# V32F20x_CM33 register map
File version: 1.0.3
CPU: CM33 r0p4, little endian, MPU, FPU, DSP, 3 interrupt priority bits, 8 SAU regions
Registers are 32-bit, read-write, reset 0x0 unless marked. A register's access mark holds for its fields unless they carry their own. Offsets are from the block's base; [hi:lo] are bit positions; lines under a group give offsets from that group; {n}, {i} and the like mark numbered series.

## ADC0 — ADC0 Peripheral Interface
Base 0x400A1000
Same registers: ADC1 0x400A1100, SEC_ADC0 0x500A1000, SEC_ADC1 0x500A1100
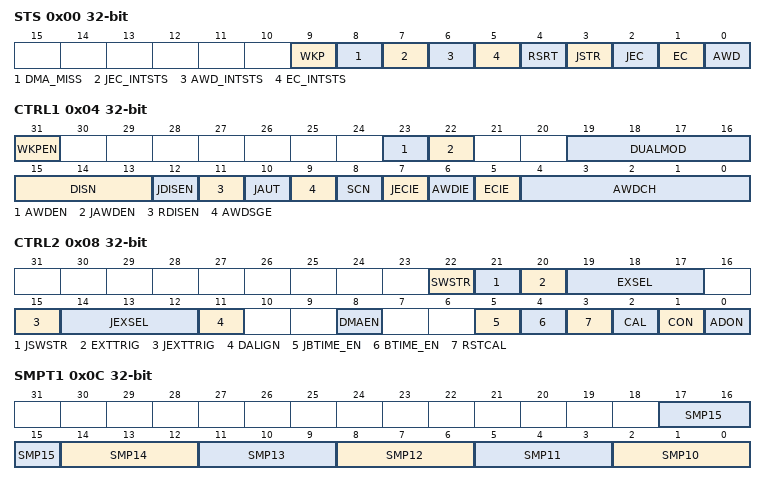
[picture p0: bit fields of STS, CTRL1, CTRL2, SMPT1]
0x00 STS — ADC status register
  [9] WKP — This bit is set by hardware when the converted voltage crosses the values programmed in the ADC_WLTR and ADC_WHTR registers and WKP is set
  [8] DMA_MISS — This bit is set when DMA has not read the data when the data is overwritten
  [7] JEC_INTSTS — Interrupt status
  [6] AWD_INTSTS — Interrupt status
  [5] EC_INTSTS — Interrupt status
  [4] RSRT — This bit is set by hardware when regular channel conversion starts
  [3] JSTR — This bit is set by hardware when injected channel group conversion starts
  [2] JEC — This bit is set by hardware at the end of all injected group channel conversion
  [1] EC — This bit is set by hardware at the end of a group channel conversion only regular
  [0] AWD — This bit is set by hardware when the converted voltage crosses the values programmed in the ADC_WLTR and ADC_WHTR registers
0x04 CTRL1 — ADC control register 1
  [31] WKPEN — Wake up enable.
  [23] AWDEN — This bit is set/reset by software.
  [22] JAWDEN — This bit is set/reset by software
  [19:16] DUALMOD — These bits are written by software to select the operating mode
  [15:13] DISN — These bits are written by software to define the number of regular channels to be converted in discontinuous mode after receiving an external trigger
  [12] JDISEN — This bit set and cleared by software to enable disable discontinuous mode on injected group channels
  [11] RDISEN — This bit set and cleared by software to enable disable Discontinuous mode on regular channels
  [10] JAUT — This bit set and cleared by software to enable disable automatic injected group conversion after regular group conversion
  [9] AWDSGE — This bit set and cleared by software to enable disable the analog watchdog on the channel identified by the AWDCH 4 0 bits
  [8] SCN — This bit is set and cleared by software to enable disable Scan mode
  [7] JECIE — This bit is set and cleared by software to enable disable the end of conversion interrupt for injected channels
  [6] AWDIE — This bit is set and cleared by software to enable disable the analog watchdog interrupt
  [5] ECIE — This bit is set and cleared by software to enable disable the end of Conversion interrupt
  [4:0] AWDCH — These bits are set and cleared by software
0x08 CTRL2 — ADC control register 2
  [22] SWSTR — This bit is set by software to start conversion and cleared by hardware as soon as conversion starts
  [21] JSWSTR — This bit is set by software and cleared by software or by hardware as soon as the conversion starts
  [20] EXTTRIG — This bit is set and cleared by software to enable disable the external trigger used to start conversion of a regular channel group
  [19:17] EXSEL — These bits select the external event used to trigger the start of conversion of a regular group
  [15] JEXTTRIG — This bit is set and cleared by software to enable disable the external trigger used to start conversion of an injected channel group
  [14:12] JEXSEL — These bits select the external event used to trigger the start of conversion of an injected group For ADC0 and ADC1 the assigned triggers are
  [11] DALIGN — This bit is set and cleared by software.
  [8] DMAEN — This bit is set and cleared by software.
  [5] JBTIME_EN — This bit combine with JEXSEL to decide the trigger source of injected
  [4] BTIME_EN — This bit combine with EXSEL to decide the trigger source of regular
  [3] RSTCAL — This bit is set by software and cleared by hardware
  [2] CAL — This bit is set by software to start the calibration
  [1] CON — This bit is set and cleared by software
  [0] ADON — This bit is set and cleared by software
0x0C SMPT1 — ADC sample time register 1
  [3n-28:3n-30] SMP{n} (n=10..15) — These bits are written by software to select the sample time individually for channel {n}
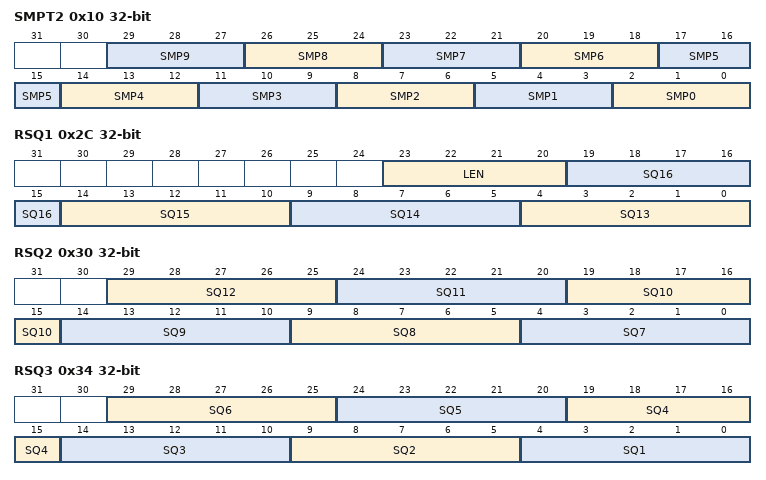
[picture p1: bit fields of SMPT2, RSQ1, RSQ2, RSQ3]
0x10 SMPT2 — ADC sample time register 2
  [3n+2:3n] SMP{n} (n=0..9) — These bits are written by software to select the sample time individually for channel {n}
{0x10+4i} JOFS{i} (i=1..4) — ADC injected channel data offset register
  [11:0] JOFST{i} — These bits are written by software to define the offset to be subtracted from the raw converted data when converting injected channels
0x24 WHTR reset 0xFFF — ADC watchdog high threshold register
  [11:0] AWHT — These bits are written by software to define the high threshold for the analog watchdog
0x28 WLTR — ADC watchdog low threshold register
  [11:0] AWLT — These bits are written by software to define the low threshold for the analog watchdog
0x2C RSQ1 — ADC regular sequence register 1
  [23:20] LEN — These bits are written by software to define the total number of conversions in the regular channel conversion sequence
  [19:15] SQ16 — These bits are written by software with the channel number 0
  [14:10] SQ15 — 15th conversion in regular sequence
  [9:5] SQ14 — 14th conversion in regular sequence
  [4:0] SQ13 — 13th conversion in regular sequence
0x30 RSQ2 — ADC regular sequence register 2
  [29:25] SQ12 — These bits are written by software with the channel number 0
  [5n-31:5n-35] SQ{n} (n=7..11) — {n}th conversion in regular sequence
0x34 RSQ3 — ADC regular sequence register 3
  [29:25] SQ6 — These bits are written by software with the channel number 0
  [5n-1:5n-5] SQ{n} (n=1..5) — {n}th conversion in regular sequence
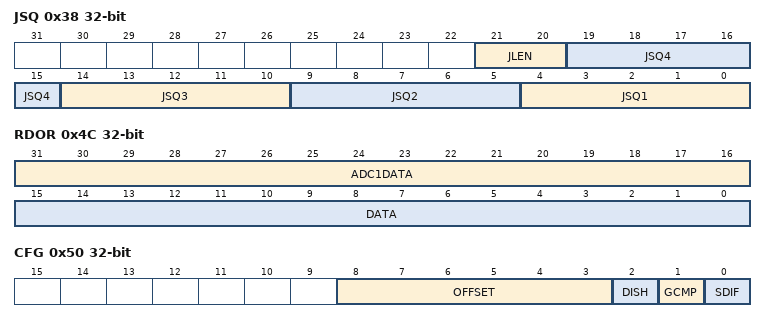
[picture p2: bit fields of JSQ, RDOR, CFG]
0x38 JSQ — ADC injected sequence register
  [21:20] JLEN — These bits are written by software to define the total number of conversions in the injected channel conversion sequence
  [19:15] JSQ4 — Fourth conversion in injected sequence when JL 1 0 3
  [14:10] JSQ3 — third conversion in injected sequence when JL 1 0 3
  [9:5] JSQ2 — second conversion in injected sequence when JL 1 0 3
  [4:0] JSQ1 — first conversion in injected sequence when JL 1 0 3
{0x38+4i} JDOR{i} ro (i=1..4) — ADC injected data register {i}
  [15:0] JDATA{i} — These bits are read only
0x4C RDOR ro — ADC regular data register
  [31:16] ADC1DATA — In ADC0 In dual mode these bits contain the regular data of ADC1
  [15:0] DATA — These bits are read only
0x50 CFG — ADC configure register
  [8:3] OFFSET — Offset setup
  [2] DISH — 0: Normal
  [1] GCMP — Internal delay time select
  [0] SDIF — analog signal mode select signal
